# W7500x register map
Vendor: WIZnet; File version: 1.0.0
CPU: CM0 r0p0, little endian, no MPU, no FPU, 2 interrupt priority bits
Registers are 32-bit, read-write, reset 0x0 unless marked. A register's access mark holds for its fields unless they carry their own. Offsets are from the block's base; [hi:lo] are bit positions; {n}, {i} and the like mark numbered series.

## PWM
Base 0x40005800
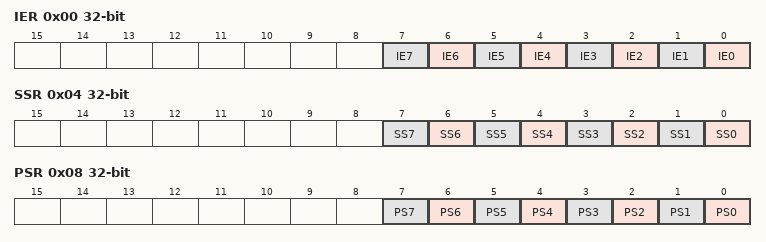
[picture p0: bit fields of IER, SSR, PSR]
0x00 IER — Interrupt enable register
  [all] fields
    0=Disable; 1=Enable
  [n] IE{n} (n=0..7) — Channel {n}
0x04 SSR — Start Stop register
  [all] fields
    0=Stop; 1=Start
  [n] SS{n} (n=0..7) — Channel {n}
0x08 PSR — Pause register
  [all] fields
    0=NotPaused; 1=Paused
  [n] PS{n} (n=0..7) — Channel {n}

## PWM0
Base 0x40005000
Same registers: PWM1 0x40005100, PWM2 0x40005200, PWM3 0x40005300, PWM4 0x40005400, PWM5 0x40005500, PWM6 0x40005600, PWM7 0x40005700
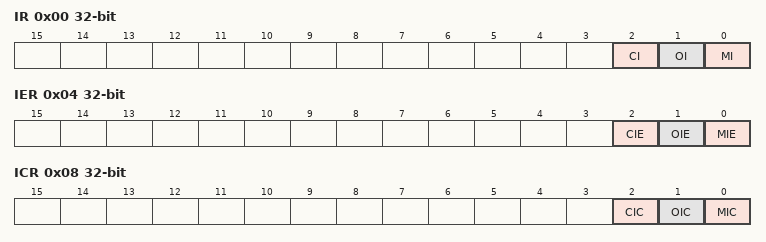
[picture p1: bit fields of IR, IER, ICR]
0x00 IR ro — Interrupt register
  [all] fields
    0=NotOccured; 1=Occured
  [2] CI — Capture Interrupt occurs
  [1] OI — Overflow Interrupt occurs
  [0] MI — Match Interrupt occurs
0x04 IER — Interrupt enable register
  [all] fields
    0=NotEnabled; 1=Enabled
  [2] CIE — Capture Interrupt Enable
  [1] OIE — Overflow Interrupt Enable
  [0] MIE — Match Interrupt Enable
0x08 ICR wo — Interrupt clear register
  [all] fields
    1=Clear
  [2] CIC — Capture Interrupt is cleared
  [1] OIC — Overflow Interrupt is cleared
  [0] MIC — Match Interrupt is cleared
0x0C TCR ro — Timer/Counter register
  [31:0] TCR — Timer/Counter
0x10 PCR ro — Prescale counter register
  [5:0] PCR — Prescale Counter
0x14 PR — Prescale register
  [5:0] PR — Prescale
0x18 MR — Match register
  [31:0] MR — Match
0x1C LR — Limit register
  [31:0] LR — Limit
0x20 UDMR — Up-Down mode register
  [0] UDM — Up-Down mode
    0=Up; 1=Down
0x24 TCMR — Timer/Counter mode register
  [1:0] TCM — TCM[1:0] bits (Timer/Counter mode)
    0=Timer; 1=CounterRising; 2=CounterFalling; 3=CounterToggle
0x28 PEEER — PWM output enable and external input enable register
  [1:0] PEEE — PWM output Enable and External input Enable
    0=OutDisableInDisable; 1=OutDisableInEnable; 2=OutEnableInDisable
0x2C CMR — Capture mode register
  [0] CM — Capture mode
    0=RisingEdge; 1=FallingEdge
0x30 CR ro — Capture register
  [31:0] CR — Capture
0x34 PDMR — Periodic mode register
  [0] PDM — Periodic Mode
    0=Periodic; 1=OneShot
0x38 DZER — Dead-zone enable register
  [0] DZE — Dead Zone Enable
    0=Disable; 1=Enable
0x3C DZCR — Dead-zone counter register
  [9:0] DZC — Dead Zone Counter value

## UART2
Base 0x40006000
0x00 DR — Data register
  [7:0] DATA — Receive (READ)/Transmit (WRITE) data
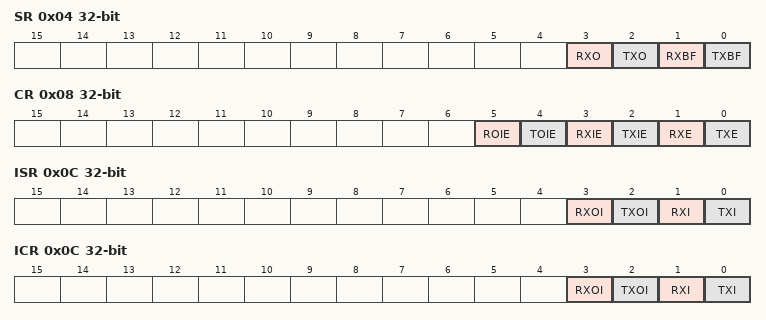
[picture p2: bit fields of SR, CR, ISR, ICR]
0x04 SR — Status register
  [3] RXO — RX buffer overrun, wirte 1 to clear
  [2] TXO — TX buffer overrun, wirte 1 to clear
  [1] RXBF — RX buffer full, read only
  [0] TXBF — TX buffer full, read only
0x08 CR — Control register
  [5] ROIE — RX overrun interrupt enable
  [4] TOIE — TX overrun interrupt enable
  [3] RXIE — RX interrupt enable
  [2] TXIE — TX interrupt enable
  [1] RXE — RX enable
  [0] TXE — TX enable
0x0C ISR ro — Interrupt Status register
  [3] RXOI — Receive Overrun Interrupt
  [2] TXOI — Transmit Overrun Interrupt
  [1] RXI — Receive Interrupt
  [0] TXI — Transmit Interrupt
0x0C ICR wo — Interrupt Clear register
  [3] RXOI — Receive Overrun Interrupt. Wirte 1 to clear
  [2] TXOI — Transmit Overrun Interrupt. Wirte 1 to clear
  [1] RXI — Receive Interrupt. Wirte 1 to clear
  [0] TXI — Transmit Interrupt. Wirte 1 to clear
0x10 BDR — Baudrate Divider register
  [19:0] BAUDDIV — Baud rate divider

## RNG
Base 0x40007000
0x00 RUN — RNG run register
  [0] RUN — RUN RNG shift flag
    0=Stop; 1=Run
0x04 SEED — RNG seed value register
  [31:0] SEED — seed value of random number generator shift register
0x08 CLKSEL — RNG Clock source select register
  [0] CLKSEL — select clock source register of RNG shift register
    0=RNG (refer to clock generator block); 1=PCLK
0x0C MODE — RNG MODE select register
  [0] MODE — RNG run mode select register
    0=PLL_LOCK (which is for power on random number); 1=RNG_RUN
0x10 RN ro — RNG random number value register
  [31:0] RN — random number of RNG shift register
0x14 POLY reset 0xE0000202 — RNG polynomial register
  [31:0] POLY — 32bit polynomial of random number generator
